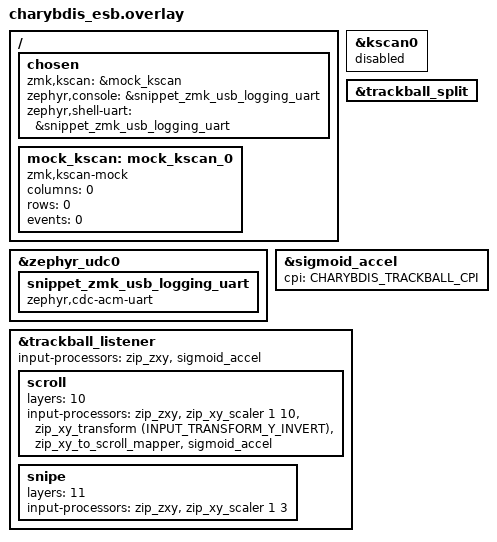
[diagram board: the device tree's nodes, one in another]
#include "../charybdis/charybdis.dtsi"
#include "../charybdis/charybdis_trackball_cpi.dtsi"
#include "charybdis_esb_addr.dtsi"
#include <input/processors/xyz.dtsi>
#include <behaviors/input_processor_sigmoid_accel.dtsi>

/ {
    chosen {
        zmk,kscan = &mock_kscan;
        zephyr,console = &snippet_zmk_usb_logging_uart;
        zephyr,shell-uart = &snippet_zmk_usb_logging_uart;
    };

    mock_kscan: mock_kscan_0 {
        compatible = "zmk,kscan-mock";
        columns = <0>;
        rows = <0>;
        events = <0>;
    };
};

&zephyr_udc0 {
    snippet_zmk_usb_logging_uart: snippet_zmk_usb_logging_uart {
        compatible = "zephyr,cdc-acm-uart";
    };
};

&kscan0 {
    status = "disabled";
};

&trackball_split {
    status = "okay";
};

&sigmoid_accel {
    cpi = <CHARYBDIS_TRACKBALL_CPI>;
};

&trackball_listener {
    status = "okay";
    input-processors = <&zip_zxy>, <&sigmoid_accel>;

    scroll {
        layers = <10>;
        input-processors = <&zip_zxy>, <&zip_xy_scaler 1 10>, <&zip_xy_transform (INPUT_TRANSFORM_Y_INVERT)>, <&zip_xy_to_scroll_mapper>, <&sigmoid_accel>;
    };

    snipe {
        layers = <11>;
        input-processors = <&zip_zxy>, <&zip_xy_scaler 1 3>;
    };
};
